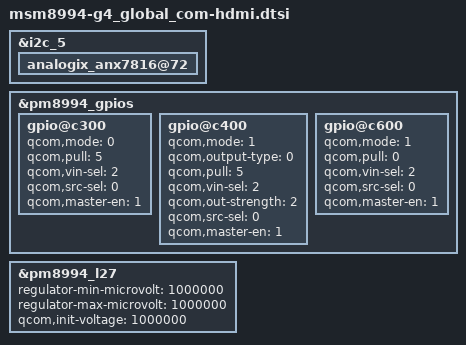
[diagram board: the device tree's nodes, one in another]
/* Copyright (c) 2012, Code Aurora Forum. All rights reserved.
 *
 * This program is free software; you can redistribute it and/or modify
 * it under the terms of the GNU General Public License version 2 and
 * only version 2 as published by the Free Software Foundation.
 *
 * This program is distributed in the hope that it will be useful,
 * but WITHOUT ANY WARRANTY; without even the implied warranty of
 * MERCHANTABILITY or FITNESS FOR A PARTICULAR PURPOSE.  See the
 * GNU General Public License for more details.
 */
#include "../msm8994-g4_common/msm8994-common-hdmi.dtsi"

&i2c_5{
	analogix_anx7816@72 {
		status = "ok";
	};
};
&pm8994_gpios {
	gpio@c300 {
		qcom,mode = <0>;
		qcom,pull = <5>;
		qcom,vin-sel = <2>;
		qcom,src-sel = <0>;
		qcom,master-en = <1>;
	};

	gpio@c400 {
		qcom,mode = <1>;
		qcom,output-type = <0>;
		qcom,pull = <5>;
		qcom,vin-sel = <2>;
		qcom,out-strength = <2>;
		qcom,src-sel = <0>;
		qcom,master-en = <1>;
	};
	gpio@c600 {
		qcom,mode = <1>;
		qcom,pull = <0>;
		qcom,vin-sel = <2>;
		qcom,src-sel = <0>;
		qcom,master-en = <1>;
	};
};


&pm8994_l27 {
	regulator-min-microvolt = <1000000>;
	regulator-max-microvolt = <1000000>;
	qcom,init-voltage = <1000000>;
};

